AUTOSAR XML (schema 4-3-0)
package /ComponentTypes
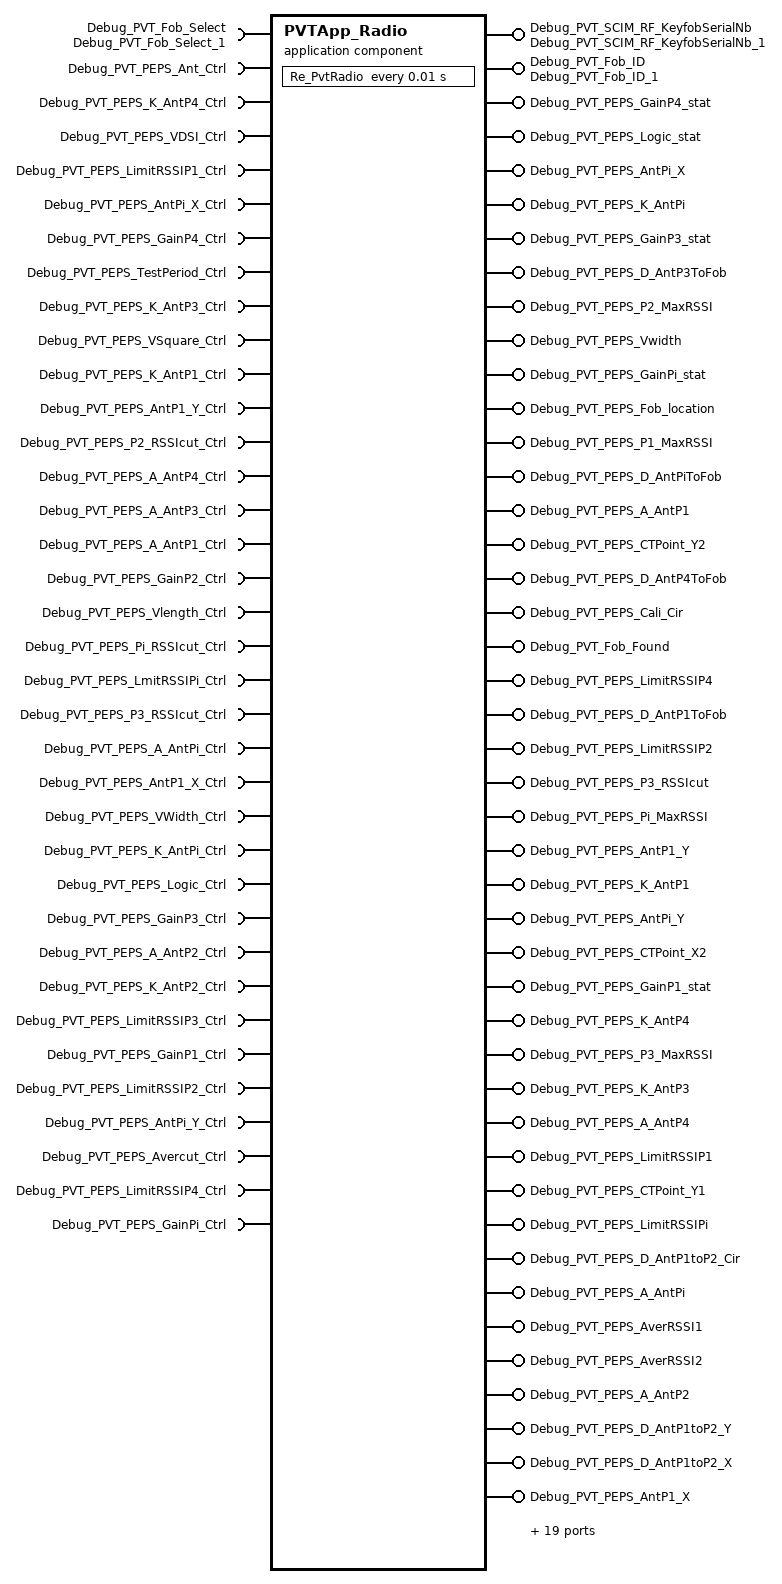
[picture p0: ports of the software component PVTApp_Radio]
  application sw component type PVTApp_Radio
    63 x provide port:
      Debug_PVT_SCIM_RF_KeyfobSerialNb: nonqueued-sender-com-spec{data-element=Debug_PVT_SCIM_RF_KeyfobSerialNb, init-value=0}, provided-interface=Debug_PVT_SCIM_RF_KeyfobSerialNb_1
      Debug_PVT_Fob_ID: nonqueued-sender-com-spec{data-element=Debug_PVT_Fob_ID, init-value=0}, provided-interface=Debug_PVT_Fob_ID_1
      Debug_PVT_PEPS_GainP4_stat: nonqueued-sender-com-spec{data-element=Debug_PVT_PEPS_GainP4_stat, init-value=0}, provided-interface=Debug_PVT_PEPS_GainP4_stat
      Debug_PVT_PEPS_Logic_stat: nonqueued-sender-com-spec{data-element=Debug_PVT_PEPS_Logic_stat, init-value=0}, provided-interface=Debug_PVT_PEPS_Logic_stat
      Debug_PVT_PEPS_AntPi_X: nonqueued-sender-com-spec{data-element=Debug_PVT_PEPS_AntPi_X, init-value=0}, provided-interface=Debug_PVT_PEPS_AntPi_X
      Debug_PVT_PEPS_K_AntPi: nonqueued-sender-com-spec{data-element=Debug_PVT_PEPS_K_AntPi, init-value=0}, provided-interface=Debug_PVT_PEPS_K_AntPi
      Debug_PVT_PEPS_GainP3_stat: nonqueued-sender-com-spec{data-element=Debug_PVT_PEPS_GainP3_stat, init-value=0}, provided-interface=Debug_PVT_PEPS_GainP3_stat
      Debug_PVT_PEPS_D_AntP3ToFob: nonqueued-sender-com-spec{data-element=Debug_PVT_PEPS_D_AntP3ToFob, init-value=0}, provided-interface=Debug_PVT_PEPS_D_AntP3ToFob
      Debug_PVT_PEPS_P2_MaxRSSI: nonqueued-sender-com-spec{data-element=Debug_PVT_PEPS_P2_MaxRSSI, init-value=0}, provided-interface=Debug_PVT_PEPS_P2_MaxRSSI
      Debug_PVT_PEPS_Vwidth: nonqueued-sender-com-spec{data-element=Debug_PVT_PEPS_Vwidth, init-value=0}, provided-interface=Debug_PVT_PEPS_Vwidth
      Debug_PVT_PEPS_GainPi_stat: nonqueued-sender-com-spec{data-element=Debug_PVT_PEPS_GainPi_stat, init-value=0}, provided-interface=Debug_PVT_PEPS_GainPi_stat
      Debug_PVT_PEPS_Fob_location: nonqueued-sender-com-spec{data-element=Debug_PVT_PEPS_Fob_location, init-value=0}, provided-interface=Debug_PVT_PEPS_Fob_location
      Debug_PVT_PEPS_P1_MaxRSSI: nonqueued-sender-com-spec{data-element=Debug_PVT_PEPS_P1_MaxRSSI, init-value=0}, provided-interface=Debug_PVT_PEPS_P1_MaxRSSI
      Debug_PVT_PEPS_D_AntPiToFob: nonqueued-sender-com-spec{data-element=Debug_PVT_PEPS_D_AntPiToFob, init-value=0}, provided-interface=Debug_PVT_PEPS_D_AntPiToFob
      Debug_PVT_PEPS_A_AntP1: nonqueued-sender-com-spec{data-element=Debug_PVT_PEPS_A_AntP1, init-value=0}, provided-interface=Debug_PVT_PEPS_A_AntP1
      Debug_PVT_PEPS_CTPoint_Y2: nonqueued-sender-com-spec{data-element=Debug_PVT_PEPS_CTPoint_Y2, init-value=0}, provided-interface=Debug_PVT_PEPS_CTPoint_Y2
      Debug_PVT_PEPS_D_AntP4ToFob: nonqueued-sender-com-spec{data-element=Debug_PVT_PEPS_D_AntP4ToFob, init-value=0}, provided-interface=Debug_PVT_PEPS_D_AntP4ToFob
      Debug_PVT_PEPS_Cali_Cir: nonqueued-sender-com-spec{data-element=Debug_PVT_PEPS_Cali_Cir, init-value=0}, provided-interface=Debug_PVT_PEPS_Cali_Cir
      Debug_PVT_Fob_Found: nonqueued-sender-com-spec{data-element=Debug_PVT_Fob_Found, init-value=0}, provided-interface=Debug_PVT_Fob_Found
      Debug_PVT_PEPS_LimitRSSIP4: nonqueued-sender-com-spec{data-element=Debug_PVT_PEPS_LimitRSSIP4, init-value=0}, provided-interface=Debug_PVT_PEPS_LimitRSSIP4
      Debug_PVT_PEPS_D_AntP1ToFob: nonqueued-sender-com-spec{data-element=Debug_PVT_PEPS_D_AntP1ToFob, init-value=0}, provided-interface=Debug_PVT_PEPS_D_AntP1ToFob
      Debug_PVT_PEPS_LimitRSSIP2: nonqueued-sender-com-spec{data-element=Debug_PVT_PEPS_LimitRSSIP2, init-value=0}, provided-interface=Debug_PVT_PEPS_LimitRSSIP2
      Debug_PVT_PEPS_P3_RSSIcut: nonqueued-sender-com-spec{data-element=Debug_PVT_PEPS_P3_RSSIcut, init-value=0}, provided-interface=Debug_PVT_PEPS_P3_RSSIcut
      Debug_PVT_PEPS_Pi_MaxRSSI: nonqueued-sender-com-spec{data-element=Debug_PVT_PEPS_Pi_MaxRSSI, init-value=0}, provided-interface=Debug_PVT_PEPS_Pi_MaxRSSI
      Debug_PVT_PEPS_AntP1_Y: nonqueued-sender-com-spec{data-element=Debug_PVT_PEPS_AntP1_Y, init-value=0}, provided-interface=Debug_PVT_PEPS_AntP1_Y
      Debug_PVT_PEPS_K_AntP1: nonqueued-sender-com-spec{data-element=Debug_PVT_PEPS_K_AntP1, init-value=0}, provided-interface=Debug_PVT_PEPS_K_AntP1
      Debug_PVT_PEPS_AntPi_Y: nonqueued-sender-com-spec{data-element=Debug_PVT_PEPS_AntPi_Y, init-value=0}, provided-interface=Debug_PVT_PEPS_AntPi_Y
      Debug_PVT_PEPS_CTPoint_X2: nonqueued-sender-com-spec{data-element=Debug_PVT_PEPS_CTPoint_X2, init-value=0}, provided-interface=Debug_PVT_PEPS_CTPoint_X2
      Debug_PVT_PEPS_GainP1_stat: nonqueued-sender-com-spec{data-element=Debug_PVT_PEPS_GainP1_stat, init-value=0}, provided-interface=Debug_PVT_PEPS_GainP1_stat
      Debug_PVT_PEPS_K_AntP4: nonqueued-sender-com-spec{data-element=Debug_PVT_PEPS_K_AntP4, init-value=0}, provided-interface=Debug_PVT_PEPS_K_AntP4
      Debug_PVT_PEPS_P3_MaxRSSI: nonqueued-sender-com-spec{data-element=Debug_PVT_PEPS_P3_MaxRSSI, init-value=0}, provided-interface=Debug_PVT_PEPS_P3_MaxRSSI
      Debug_PVT_PEPS_K_AntP3: nonqueued-sender-com-spec{data-element=Debug_PVT_PEPS_K_AntP3, init-value=0}, provided-interface=Debug_PVT_PEPS_K_AntP3
      Debug_PVT_PEPS_A_AntP4: nonqueued-sender-com-spec{data-element=Debug_PVT_PEPS_A_AntP4, init-value=0}, provided-interface=Debug_PVT_PEPS_A_AntP4
      Debug_PVT_PEPS_LimitRSSIP1: nonqueued-sender-com-spec{data-element=Debug_PVT_PEPS_LimitRSSIP1, init-value=0}, provided-interface=Debug_PVT_PEPS_LimitRSSIP1
      Debug_PVT_PEPS_CTPoint_Y1: nonqueued-sender-com-spec{data-element=Debug_PVT_PEPS_CTPoint_Y1, init-value=0}, provided-interface=Debug_PVT_PEPS_CTPoint_Y1
      Debug_PVT_PEPS_LimitRSSIPi: nonqueued-sender-com-spec{data-element=Debug_PVT_PEPS_LimitRSSIPi, init-value=0}, provided-interface=Debug_PVT_PEPS_LimitRSSIPi
      Debug_PVT_PEPS_D_AntP1toP2_Cir: nonqueued-sender-com-spec{data-element=Debug_PVT_PEPS_D_AntP1toP2_Cir, init-value=0}, provided-interface=Debug_PVT_PEPS_D_AntP1toP2_Cir
      Debug_PVT_PEPS_A_AntPi: nonqueued-sender-com-spec{data-element=Debug_PVT_PEPS_A_AntPi, init-value=0}, provided-interface=Debug_PVT_PEPS_A_AntPi
      Debug_PVT_PEPS_AverRSSI1: nonqueued-sender-com-spec{data-element=Debug_PVT_PEPS_AverRSSI1, init-value=0}, provided-interface=Debug_PVT_PEPS_AverRSSI1
      Debug_PVT_PEPS_AverRSSI2: nonqueued-sender-com-spec{data-element=Debug_PVT_PEPS_AverRSSI2, init-value=0}, provided-interface=Debug_PVT_PEPS_AverRSSI2
      Debug_PVT_PEPS_A_AntP2: nonqueued-sender-com-spec{data-element=Debug_PVT_PEPS_A_AntP2, init-value=0}, provided-interface=Debug_PVT_PEPS_A_AntP2
      Debug_PVT_PEPS_D_AntP1toP2_Y: nonqueued-sender-com-spec{data-element=Debug_PVT_PEPS_D_AntP1toP2_Y, init-value=0}, provided-interface=Debug_PVT_PEPS_D_AntP1toP2_Y
      Debug_PVT_PEPS_D_AntP1toP2_X: nonqueued-sender-com-spec{data-element=Debug_PVT_PEPS_D_AntP1toP2_X, init-value=0}, provided-interface=Debug_PVT_PEPS_D_AntP1toP2_X
      Debug_PVT_PEPS_AntP1_X: nonqueued-sender-com-spec{data-element=Debug_PVT_PEPS_AntP1_X, init-value=0}, provided-interface=Debug_PVT_PEPS_AntP1_X
      Debug_PVT_PEPS_Vlength: nonqueued-sender-com-spec{data-element=Debug_PVT_PEPS_Vlength, init-value=0}, provided-interface=Debug_PVT_PEPS_Vlength
      Debug_PVT_PEPS_AntCtrl_stat: nonqueued-sender-com-spec{data-element=Debug_PVT_PEPS_AntCtrl_stat, init-value=0}, provided-interface=Debug_PVT_PEPS_AntCtrl_stat
      Debug_PVT_PEPS_Vsquare: nonqueued-sender-com-spec{data-element=Debug_PVT_PEPS_Vsquare, init-value=0}, provided-interface=Debug_PVT_PEPS_Vsquare
      Debug_PVT_PEPS_D_AntP2ToFob: nonqueued-sender-com-spec{data-element=Debug_PVT_PEPS_D_AntP2ToFob, init-value=0}, provided-interface=Debug_PVT_PEPS_D_AntP2ToFob
      Debug_PVT_PEPS_K_AntP2: nonqueued-sender-com-spec{data-element=Debug_PVT_PEPS_K_AntP2, init-value=0}, provided-interface=Debug_PVT_PEPS_K_AntP2
      Debug_PVT_PEPS_P2_RSSIcut: nonqueued-sender-com-spec{data-element=Debug_PVT_PEPS_P2_RSSIcut, init-value=0}, provided-interface=Debug_PVT_PEPS_P2_RSSIcut
      Debug_PVT_PEPS_GainP2_stat: nonqueued-sender-com-spec{data-element=Debug_PVT_PEPS_GainP2_stat, init-value=0}, provided-interface=Debug_PVT_PEPS_GainP2_stat
      Debug_PVT_PEPS_A_AntP3: nonqueued-sender-com-spec{data-element=Debug_PVT_PEPS_A_AntP3, init-value=0}, provided-interface=Debug_PVT_PEPS_A_AntP3
      Debug_PVT_PEPS_LimitRSSIP3: nonqueued-sender-com-spec{data-element=Debug_PVT_PEPS_LimitRSSIP3, init-value=0}, provided-interface=Debug_PVT_PEPS_LimitRSSIP3
      Debug_PVT_PEPS_CTPoint_X1: nonqueued-sender-com-spec{data-element=Debug_PVT_PEPS_CTPoint_X1, init-value=0}, provided-interface=Debug_PVT_PEPS_CTPoint_X1
      Debug_PVT_PEPS_VDSI_stat: nonqueued-sender-com-spec{data-element=Debug_PVT_PEPS_VDSI_stat, init-value=0}, provided-interface=Debug_PVT_PEPS_VDSI_stat
      Debug_PVT_SCIM_RF_RollingCounter: nonqueued-sender-com-spec{data-element=Debug_PVT_SCIM_RF_RollingCounter, init-value=0}, provided-interface=Debug_PVT_SCIM_RF_RollingCounter_1
      Debug_PVT_PEPS_P4_MaxRSSI: nonqueued-sender-com-spec{data-element=Debug_PVT_PEPS_P4_MaxRSSI, init-value=0}, provided-interface=Debug_PVT_PEPS_P4_MaxRSSI
      Debug_PVT_PEPS_K_Cir: nonqueued-sender-com-spec{data-element=Debug_PVT_PEPS_K_Cir, init-value=0}, provided-interface=Debug_PVT_PEPS_K_Cir
      Debug_PVT_Fob_RF_RollingCounter: nonqueued-sender-com-spec{data-element=Debug_PVT_Fob_RF_RollingCounter, init-value=0}, provided-interface=Debug_PVT_Fob_RF_RollingCounter_1
      Debug_PVT_PEPS_DecRSSI: nonqueued-sender-com-spec{data-element=Debug_PVT_PEPS_DecRSSI, init-value=0}, provided-interface=Debug_PVT_PEPS_DecRSSI
      Debug_PVT_PEPS_Avercut: nonqueued-sender-com-spec{data-element=Debug_PVT_PEPS_Avercut, init-value=0}, provided-interface=Debug_PVT_PEPS_Avercut
      Debug_PVT_PEPS_TestPeriod_stat: nonqueued-sender-com-spec{data-element=Debug_PVT_PEPS_TestPeriod_stat, init-value=0}, provided-interface=Debug_PVT_PEPS_TestPeriod_stat
      Debug_PVT_PEPS_Pi_RSSIcut: nonqueued-sender-com-spec{data-element=Debug_PVT_PEPS_Pi_RSSIcut, init-value=0}, provided-interface=Debug_PVT_PEPS_Pi_RSSIcut
    36 x require port:
      Debug_PVT_Fob_Select: nonqueued-receiver-com-spec{data-element=Debug_PVT_Fob_Select, init-value=0}, required-interface=Debug_PVT_Fob_Select_1
      Debug_PVT_PEPS_Ant_Ctrl: nonqueued-receiver-com-spec{data-element=Debug_PVT_PEPS_Ant_Ctrl, init-value=0}, required-interface=Debug_PVT_PEPS_Ant_Ctrl
      Debug_PVT_PEPS_K_AntP4_Ctrl: nonqueued-receiver-com-spec{data-element=Debug_PVT_PEPS_K_AntP4_Ctrl, init-value=0}, required-interface=Debug_PVT_PEPS_K_AntP4_Ctrl
      Debug_PVT_PEPS_VDSI_Ctrl: nonqueued-receiver-com-spec{data-element=Debug_PVT_PEPS_VDSI_Ctrl, init-value=0}, required-interface=Debug_PVT_PEPS_VDSI_Ctrl
      Debug_PVT_PEPS_LimitRSSIP1_Ctrl: nonqueued-receiver-com-spec{data-element=Debug_PVT_PEPS_LimitRSSIP1_Ctrl, init-value=0}, required-interface=Debug_PVT_PEPS_LimitRSSIP1_Ctrl
      Debug_PVT_PEPS_AntPi_X_Ctrl: nonqueued-receiver-com-spec{data-element=Debug_PVT_PEPS_AntPi_X_Ctrl, init-value=0}, required-interface=Debug_PVT_PEPS_AntPi_X_Ctrl
      Debug_PVT_PEPS_GainP4_Ctrl: nonqueued-receiver-com-spec{data-element=Debug_PVT_PEPS_GainP4_Ctrl, init-value=0}, required-interface=Debug_PVT_PEPS_GainP4_Ctrl
      Debug_PVT_PEPS_TestPeriod_Ctrl: nonqueued-receiver-com-spec{data-element=Debug_PVT_PEPS_TestPeriod_Ctrl, init-value=0}, required-interface=Debug_PVT_PEPS_TestPeriod_Ctrl
      Debug_PVT_PEPS_K_AntP3_Ctrl: nonqueued-receiver-com-spec{data-element=Debug_PVT_PEPS_K_AntP3_Ctrl, init-value=0}, required-interface=Debug_PVT_PEPS_K_AntP3_Ctrl
      Debug_PVT_PEPS_VSquare_Ctrl: nonqueued-receiver-com-spec{data-element=Debug_PVT_PEPS_VSquare_Ctrl, init-value=0}, required-interface=Debug_PVT_PEPS_VSquare_Ctrl
      Debug_PVT_PEPS_K_AntP1_Ctrl: nonqueued-receiver-com-spec{data-element=Debug_PVT_PEPS_K_AntP1_Ctrl, init-value=0}, required-interface=Debug_PVT_PEPS_K_AntP1_Ctrl
      Debug_PVT_PEPS_AntP1_Y_Ctrl: nonqueued-receiver-com-spec{data-element=Debug_PVT_PEPS_AntP1_Y_Ctrl, init-value=0}, required-interface=Debug_PVT_PEPS_AntP1_Y_Ctrl
      Debug_PVT_PEPS_P2_RSSIcut_Ctrl: nonqueued-receiver-com-spec{data-element=Debug_PVT_PEPS_P2_RSSIcut_Ctrl, init-value=0}, required-interface=Debug_PVT_PEPS_P2_RSSIcut_Ctrl
      Debug_PVT_PEPS_A_AntP4_Ctrl: nonqueued-receiver-com-spec{data-element=Debug_PVT_PEPS_A_AntP4_Ctrl, init-value=0}, required-interface=Debug_PVT_PEPS_A_AntP4_Ctrl
      Debug_PVT_PEPS_A_AntP3_Ctrl: nonqueued-receiver-com-spec{data-element=Debug_PVT_PEPS_A_AntP3_Ctrl, init-value=0}, required-interface=Debug_PVT_PEPS_A_AntP3_Ctrl
      Debug_PVT_PEPS_A_AntP1_Ctrl: nonqueued-receiver-com-spec{data-element=Debug_PVT_PEPS_A_AntP1_Ctrl, init-value=0}, required-interface=Debug_PVT_PEPS_A_AntP1_Ctrl
      Debug_PVT_PEPS_GainP2_Ctrl: nonqueued-receiver-com-spec{data-element=Debug_PVT_PEPS_GainP2_Ctrl, init-value=0}, required-interface=Debug_PVT_PEPS_GainP2_Ctrl
      Debug_PVT_PEPS_Vlength_Ctrl: nonqueued-receiver-com-spec{data-element=Debug_PVT_PEPS_Vlength_Ctrl, init-value=0}, required-interface=Debug_PVT_PEPS_Vlength_Ctrl
      Debug_PVT_PEPS_Pi_RSSIcut_Ctrl: nonqueued-receiver-com-spec{data-element=Debug_PVT_PEPS_Pi_RSSIcut_Ctrl, init-value=0}, required-interface=Debug_PVT_PEPS_Pi_RSSIcut_Ctrl
      Debug_PVT_PEPS_LmitRSSIPi_Ctrl: nonqueued-receiver-com-spec{data-element=Debug_PVT_PEPS_LmitRSSIPi_Ctrl, init-value=0}, required-interface=Debug_PVT_PEPS_LmitRSSIPi_Ctrl
      Debug_PVT_PEPS_P3_RSSIcut_Ctrl: nonqueued-receiver-com-spec{data-element=Debug_PVT_PEPS_P3_RSSIcut_Ctrl, init-value=0}, required-interface=Debug_PVT_PEPS_P3_RSSIcut_Ctrl
      Debug_PVT_PEPS_A_AntPi_Ctrl: nonqueued-receiver-com-spec{data-element=Debug_PVT_PEPS_A_AntPi_Ctrl, init-value=0}, required-interface=Debug_PVT_PEPS_A_AntPi_Ctrl
      Debug_PVT_PEPS_AntP1_X_Ctrl: nonqueued-receiver-com-spec{data-element=Debug_PVT_PEPS_AntP1_X_Ctrl, init-value=0}, required-interface=Debug_PVT_PEPS_AntP1_X_Ctrl
      Debug_PVT_PEPS_VWidth_Ctrl: nonqueued-receiver-com-spec{data-element=Debug_PVT_PEPS_VWidth_Ctrl, init-value=0}, required-interface=Debug_PVT_PEPS_VWidth_Ctrl
      Debug_PVT_PEPS_K_AntPi_Ctrl: nonqueued-receiver-com-spec{data-element=Debug_PVT_PEPS_K_AntPi_Ctrl, init-value=0}, required-interface=Debug_PVT_PEPS_K_AntPi_Ctrl
      Debug_PVT_PEPS_Logic_Ctrl: nonqueued-receiver-com-spec{data-element=Debug_PVT_PEPS_Logic_Ctrl, init-value=0}, required-interface=Debug_PVT_PEPS_Logic_Ctrl
      Debug_PVT_PEPS_GainP3_Ctrl: nonqueued-receiver-com-spec{data-element=Debug_PVT_PEPS_GainP3_Ctrl, init-value=0}, required-interface=Debug_PVT_PEPS_GainP3_Ctrl
      Debug_PVT_PEPS_A_AntP2_Ctrl: nonqueued-receiver-com-spec{data-element=Debug_PVT_PEPS_A_AntP2_Ctrl, init-value=0}, required-interface=Debug_PVT_PEPS_A_AntP2_Ctrl
      Debug_PVT_PEPS_K_AntP2_Ctrl: nonqueued-receiver-com-spec{data-element=Debug_PVT_PEPS_K_AntP2_Ctrl, init-value=0}, required-interface=Debug_PVT_PEPS_K_AntP2_Ctrl
      Debug_PVT_PEPS_LimitRSSIP3_Ctrl: nonqueued-receiver-com-spec{data-element=Debug_PVT_PEPS_LimitRSSIP3_Ctrl, init-value=0}, required-interface=Debug_PVT_PEPS_LimitRSSIP3_Ctrl
      Debug_PVT_PEPS_GainP1_Ctrl: nonqueued-receiver-com-spec{data-element=Debug_PVT_PEPS_GainP1_Ctrl, init-value=0}, required-interface=Debug_PVT_PEPS_GainP1_Ctrl
      Debug_PVT_PEPS_LimitRSSIP2_Ctrl: nonqueued-receiver-com-spec{data-element=Debug_PVT_PEPS_LimitRSSIP2_Ctrl, init-value=0}, required-interface=Debug_PVT_PEPS_LimitRSSIP2_Ctrl
      Debug_PVT_PEPS_AntPi_Y_Ctrl: nonqueued-receiver-com-spec{data-element=Debug_PVT_PEPS_AntPi_Y_Ctrl, init-value=0}, required-interface=Debug_PVT_PEPS_AntPi_Y_Ctrl
      Debug_PVT_PEPS_Avercut_Ctrl: nonqueued-receiver-com-spec{data-element=Debug_PVT_PEPS_Avercut_Ctrl, init-value=0}, required-interface=Debug_PVT_PEPS_Avercut_Ctrl
      Debug_PVT_PEPS_LimitRSSIP4_Ctrl: nonqueued-receiver-com-spec{data-element=Debug_PVT_PEPS_LimitRSSIP4_Ctrl, init-value=0}, required-interface=Debug_PVT_PEPS_LimitRSSIP4_Ctrl
      Debug_PVT_PEPS_GainPi_Ctrl: nonqueued-receiver-com-spec{data-element=Debug_PVT_PEPS_GainPi_Ctrl, init-value=0}, required-interface=Debug_PVT_PEPS_GainPi_Ctrl
    behavior PVTApp_Radio_InternalBehavior
      timing event TMT_Re_PvtRadio: start-on-event=Re_PvtRadio, period=0.01
      runnable Re_PvtRadio
        data-receive-point-by-arguments:
          36 x access:
            REC_Debug_PVT_Fob_Select_Debug_PVT_Fob_Select: accessed-variable=Debug_PVT_Fob_Select.Debug_PVT_Fob_Select
            REC_Debug_PVT_PEPS_A_AntP{1..4}_Ctrl_Debug_PVT_PEPS_A_AntP{1..4}_Ctrl: accessed-variable=Debug_PVT_PEPS_A_AntP{1..4}_Ctrl.Debug_PVT_PEPS_A_AntP{1..4}_Ctrl
            REC_Debug_PVT_PEPS_A_AntPi_Ctrl_Debug_PVT_PEPS_A_AntPi_Ctrl: accessed-variable=Debug_PVT_PEPS_A_AntPi_Ctrl.Debug_PVT_PEPS_A_AntPi_Ctrl
            REC_Debug_PVT_PEPS_AntP1_X_Ctrl_Debug_PVT_PEPS_AntP1_X_Ctrl: accessed-variable=Debug_PVT_PEPS_AntP1_X_Ctrl.Debug_PVT_PEPS_AntP1_X_Ctrl
            REC_Debug_PVT_PEPS_AntP1_Y_Ctrl_Debug_PVT_PEPS_AntP1_Y_Ctrl: accessed-variable=Debug_PVT_PEPS_AntP1_Y_Ctrl.Debug_PVT_PEPS_AntP1_Y_Ctrl
            REC_Debug_PVT_PEPS_AntPi_X_Ctrl_Debug_PVT_PEPS_AntPi_X_Ctrl: accessed-variable=Debug_PVT_PEPS_AntPi_X_Ctrl.Debug_PVT_PEPS_AntPi_X_Ctrl
            REC_Debug_PVT_PEPS_AntPi_Y_Ctrl_Debug_PVT_PEPS_AntPi_Y_Ctrl: accessed-variable=Debug_PVT_PEPS_AntPi_Y_Ctrl.Debug_PVT_PEPS_AntPi_Y_Ctrl
            REC_Debug_PVT_PEPS_Ant_Ctrl_Debug_PVT_PEPS_Ant_Ctrl: accessed-variable=Debug_PVT_PEPS_Ant_Ctrl.Debug_PVT_PEPS_Ant_Ctrl
            REC_Debug_PVT_PEPS_Avercut_Ctrl_Debug_PVT_PEPS_Avercut_Ctrl: accessed-variable=Debug_PVT_PEPS_Avercut_Ctrl.Debug_PVT_PEPS_Avercut_Ctrl
            REC_Debug_PVT_PEPS_GainP{1..4}_Ctrl_Debug_PVT_PEPS_GainP{1..4}_Ctrl: accessed-variable=Debug_PVT_PEPS_GainP{1..4}_Ctrl.Debug_PVT_PEPS_GainP{1..4}_Ctrl
            REC_Debug_PVT_PEPS_GainPi_Ctrl_Debug_PVT_PEPS_GainPi_Ctrl: accessed-variable=Debug_PVT_PEPS_GainPi_Ctrl.Debug_PVT_PEPS_GainPi_Ctrl
            REC_Debug_PVT_PEPS_K_AntP{1..4}_Ctrl_Debug_PVT_PEPS_K_AntP{1..4}_Ctrl: accessed-variable=Debug_PVT_PEPS_K_AntP{1..4}_Ctrl.Debug_PVT_PEPS_K_AntP{1..4}_Ctrl
            REC_Debug_PVT_PEPS_K_AntPi_Ctrl_Debug_PVT_PEPS_K_AntPi_Ctrl: accessed-variable=Debug_PVT_PEPS_K_AntPi_Ctrl.Debug_PVT_PEPS_K_AntPi_Ctrl
            REC_Debug_PVT_PEPS_LimitRSSIP{1..4}_Ctrl_Debug_PVT_PEPS_LimitRSSIP{1..4}_Ctrl: accessed-variable=Debug_PVT_PEPS_LimitRSSIP{1..4}_Ctrl.Debug_PVT_PEPS_LimitRSSIP{1..4}_Ctrl
            REC_Debug_PVT_PEPS_LmitRSSIPi_Ctrl_Debug_PVT_PEPS_LmitRSSIPi_Ctrl: accessed-variable=Debug_PVT_PEPS_LmitRSSIPi_Ctrl.Debug_PVT_PEPS_LmitRSSIPi_Ctrl
            REC_Debug_PVT_PEPS_Logic_Ctrl_Debug_PVT_PEPS_Logic_Ctrl: accessed-variable=Debug_PVT_PEPS_Logic_Ctrl.Debug_PVT_PEPS_Logic_Ctrl
            REC_Debug_PVT_PEPS_P2_RSSIcut_Ctrl_Debug_PVT_PEPS_P2_RSSIcut_Ctrl: accessed-variable=Debug_PVT_PEPS_P2_RSSIcut_Ctrl.Debug_PVT_PEPS_P2_RSSIcut_Ctrl
            REC_Debug_PVT_PEPS_P3_RSSIcut_Ctrl_Debug_PVT_PEPS_P3_RSSIcut_Ctrl: accessed-variable=Debug_PVT_PEPS_P3_RSSIcut_Ctrl.Debug_PVT_PEPS_P3_RSSIcut_Ctrl
            REC_Debug_PVT_PEPS_Pi_RSSIcut_Ctrl_Debug_PVT_PEPS_Pi_RSSIcut_Ctrl: accessed-variable=Debug_PVT_PEPS_Pi_RSSIcut_Ctrl.Debug_PVT_PEPS_Pi_RSSIcut_Ctrl
            REC_Debug_PVT_PEPS_TestPeriod_Ctrl_Debug_PVT_PEPS_TestPeriod_Ctrl: accessed-variable=Debug_PVT_PEPS_TestPeriod_Ctrl.Debug_PVT_PEPS_TestPeriod_Ctrl
            REC_Debug_PVT_PEPS_VDSI_Ctrl_Debug_PVT_PEPS_VDSI_Ctrl: accessed-variable=Debug_PVT_PEPS_VDSI_Ctrl.Debug_PVT_PEPS_VDSI_Ctrl
            REC_Debug_PVT_PEPS_VSquare_Ctrl_Debug_PVT_PEPS_VSquare_Ctrl: accessed-variable=Debug_PVT_PEPS_VSquare_Ctrl.Debug_PVT_PEPS_VSquare_Ctrl
            REC_Debug_PVT_PEPS_VWidth_Ctrl_Debug_PVT_PEPS_VWidth_Ctrl: accessed-variable=Debug_PVT_PEPS_VWidth_Ctrl.Debug_PVT_PEPS_VWidth_Ctrl
            REC_Debug_PVT_PEPS_Vlength_Ctrl_Debug_PVT_PEPS_Vlength_Ctrl: accessed-variable=Debug_PVT_PEPS_Vlength_Ctrl.Debug_PVT_PEPS_Vlength_Ctrl
        data-send-points:
          63 x access:
            SEND_Debug_PVT_Fob_Found_Debug_PVT_Fob_Found: accessed-variable=Debug_PVT_Fob_Found.Debug_PVT_Fob_Found
            SEND_Debug_PVT_Fob_ID_Debug_PVT_Fob_ID: accessed-variable=Debug_PVT_Fob_ID.Debug_PVT_Fob_ID
            SEND_Debug_PVT_Fob_RF_RollingCounter_Debug_PVT_Fob_RF_RollingCounter: accessed-variable=Debug_PVT_Fob_RF_RollingCounter.Debug_PVT_Fob_RF_RollingCounter
            SEND_Debug_PVT_PEPS_A_AntP{1..4}_Debug_PVT_PEPS_A_AntP{1..4}: accessed-variable=Debug_PVT_PEPS_A_AntP{1..4}.Debug_PVT_PEPS_A_AntP{1..4}
            SEND_Debug_PVT_PEPS_A_AntPi_Debug_PVT_PEPS_A_AntPi: accessed-variable=Debug_PVT_PEPS_A_AntPi.Debug_PVT_PEPS_A_AntPi
            SEND_Debug_PVT_PEPS_AntCtrl_stat_Debug_PVT_PEPS_AntCtrl_stat: accessed-variable=Debug_PVT_PEPS_AntCtrl_stat.Debug_PVT_PEPS_AntCtrl_stat
            SEND_Debug_PVT_PEPS_AntP1_X_Debug_PVT_PEPS_AntP1_X: accessed-variable=Debug_PVT_PEPS_AntP1_X.Debug_PVT_PEPS_AntP1_X
            SEND_Debug_PVT_PEPS_AntP1_Y_Debug_PVT_PEPS_AntP1_Y: accessed-variable=Debug_PVT_PEPS_AntP1_Y.Debug_PVT_PEPS_AntP1_Y
            SEND_Debug_PVT_PEPS_AntPi_X_Debug_PVT_PEPS_AntPi_X: accessed-variable=Debug_PVT_PEPS_AntPi_X.Debug_PVT_PEPS_AntPi_X
            SEND_Debug_PVT_PEPS_AntPi_Y_Debug_PVT_PEPS_AntPi_Y: accessed-variable=Debug_PVT_PEPS_AntPi_Y.Debug_PVT_PEPS_AntPi_Y
            SEND_Debug_PVT_PEPS_Avercut_Debug_PVT_PEPS_Avercut: accessed-variable=Debug_PVT_PEPS_Avercut.Debug_PVT_PEPS_Avercut
            SEND_Debug_PVT_PEPS_AverRSSI1_Debug_PVT_PEPS_AverRSSI1: accessed-variable=Debug_PVT_PEPS_AverRSSI1.Debug_PVT_PEPS_AverRSSI1
            SEND_Debug_PVT_PEPS_AverRSSI2_Debug_PVT_PEPS_AverRSSI2: accessed-variable=Debug_PVT_PEPS_AverRSSI2.Debug_PVT_PEPS_AverRSSI2
            SEND_Debug_PVT_PEPS_Cali_Cir_Debug_PVT_PEPS_Cali_Cir: accessed-variable=Debug_PVT_PEPS_Cali_Cir.Debug_PVT_PEPS_Cali_Cir
            SEND_Debug_PVT_PEPS_CTPoint_X1_Debug_PVT_PEPS_CTPoint_X1: accessed-variable=Debug_PVT_PEPS_CTPoint_X1.Debug_PVT_PEPS_CTPoint_X1
            SEND_Debug_PVT_PEPS_CTPoint_X2_Debug_PVT_PEPS_CTPoint_X2: accessed-variable=Debug_PVT_PEPS_CTPoint_X2.Debug_PVT_PEPS_CTPoint_X2
            SEND_Debug_PVT_PEPS_CTPoint_Y1_Debug_PVT_PEPS_CTPoint_Y1: accessed-variable=Debug_PVT_PEPS_CTPoint_Y1.Debug_PVT_PEPS_CTPoint_Y1
            SEND_Debug_PVT_PEPS_CTPoint_Y2_Debug_PVT_PEPS_CTPoint_Y2: accessed-variable=Debug_PVT_PEPS_CTPoint_Y2.Debug_PVT_PEPS_CTPoint_Y2
            SEND_Debug_PVT_PEPS_D_AntP1ToFob_Debug_PVT_PEPS_D_AntP1ToFob: accessed-variable=Debug_PVT_PEPS_D_AntP1ToFob.Debug_PVT_PEPS_D_AntP1ToFob
            SEND_Debug_PVT_PEPS_D_AntP1toP2_Cir_Debug_PVT_PEPS_D_AntP1toP2_Cir: accessed-variable=Debug_PVT_PEPS_D_AntP1toP2_Cir.Debug_PVT_PEPS_D_AntP1toP2_Cir
            SEND_Debug_PVT_PEPS_D_AntP1toP2_X_Debug_PVT_PEPS_D_AntP1toP2_X: accessed-variable=Debug_PVT_PEPS_D_AntP1toP2_X.Debug_PVT_PEPS_D_AntP1toP2_X
            SEND_Debug_PVT_PEPS_D_AntP1toP2_Y_Debug_PVT_PEPS_D_AntP1toP2_Y: accessed-variable=Debug_PVT_PEPS_D_AntP1toP2_Y.Debug_PVT_PEPS_D_AntP1toP2_Y
            SEND_Debug_PVT_PEPS_D_AntP{2..4}ToFob_Debug_PVT_PEPS_D_AntP{2..4}ToFob: accessed-variable=Debug_PVT_PEPS_D_AntP{2..4}ToFob.Debug_PVT_PEPS_D_AntP{2..4}ToFob
            SEND_Debug_PVT_PEPS_D_AntPiToFob_Debug_PVT_PEPS_D_AntPiToFob: accessed-variable=Debug_PVT_PEPS_D_AntPiToFob.Debug_PVT_PEPS_D_AntPiToFob
            SEND_Debug_PVT_PEPS_DecRSSI_Debug_PVT_PEPS_DecRSSI: accessed-variable=Debug_PVT_PEPS_DecRSSI.Debug_PVT_PEPS_DecRSSI
            SEND_Debug_PVT_PEPS_Fob_location_Debug_PVT_PEPS_Fob_location: accessed-variable=Debug_PVT_PEPS_Fob_location.Debug_PVT_PEPS_Fob_location
            SEND_Debug_PVT_PEPS_GainP{1..4}_stat_Debug_PVT_PEPS_GainP{1..4}_stat: accessed-variable=Debug_PVT_PEPS_GainP{1..4}_stat.Debug_PVT_PEPS_GainP{1..4}_stat
            SEND_Debug_PVT_PEPS_GainPi_stat_Debug_PVT_PEPS_GainPi_stat: accessed-variable=Debug_PVT_PEPS_GainPi_stat.Debug_PVT_PEPS_GainPi_stat
            SEND_Debug_PVT_PEPS_K_AntP{1..4}_Debug_PVT_PEPS_K_AntP{1..4}: accessed-variable=Debug_PVT_PEPS_K_AntP{1..4}.Debug_PVT_PEPS_K_AntP{1..4}
            SEND_Debug_PVT_PEPS_K_AntPi_Debug_PVT_PEPS_K_AntPi: accessed-variable=Debug_PVT_PEPS_K_AntPi.Debug_PVT_PEPS_K_AntPi
            SEND_Debug_PVT_PEPS_K_Cir_Debug_PVT_PEPS_K_Cir: accessed-variable=Debug_PVT_PEPS_K_Cir.Debug_PVT_PEPS_K_Cir
            SEND_Debug_PVT_PEPS_LimitRSSIP{1..4}_Debug_PVT_PEPS_LimitRSSIP{1..4}: accessed-variable=Debug_PVT_PEPS_LimitRSSIP{1..4}.Debug_PVT_PEPS_LimitRSSIP{1..4}
            SEND_Debug_PVT_PEPS_LimitRSSIPi_Debug_PVT_PEPS_LimitRSSIPi: accessed-variable=Debug_PVT_PEPS_LimitRSSIPi.Debug_PVT_PEPS_LimitRSSIPi
            SEND_Debug_PVT_PEPS_Logic_stat_Debug_PVT_PEPS_Logic_stat: accessed-variable=Debug_PVT_PEPS_Logic_stat.Debug_PVT_PEPS_Logic_stat
            SEND_Debug_PVT_PEPS_P1_MaxRSSI_Debug_PVT_PEPS_P1_MaxRSSI: accessed-variable=Debug_PVT_PEPS_P1_MaxRSSI.Debug_PVT_PEPS_P1_MaxRSSI
            SEND_Debug_PVT_PEPS_P2_MaxRSSI_Debug_PVT_PEPS_P2_MaxRSSI: accessed-variable=Debug_PVT_PEPS_P2_MaxRSSI.Debug_PVT_PEPS_P2_MaxRSSI
            SEND_Debug_PVT_PEPS_P2_RSSIcut_Debug_PVT_PEPS_P2_RSSIcut: accessed-variable=Debug_PVT_PEPS_P2_RSSIcut.Debug_PVT_PEPS_P2_RSSIcut
            SEND_Debug_PVT_PEPS_P3_MaxRSSI_Debug_PVT_PEPS_P3_MaxRSSI: accessed-variable=Debug_PVT_PEPS_P3_MaxRSSI.Debug_PVT_PEPS_P3_MaxRSSI
            SEND_Debug_PVT_PEPS_P3_RSSIcut_Debug_PVT_PEPS_P3_RSSIcut: accessed-variable=Debug_PVT_PEPS_P3_RSSIcut.Debug_PVT_PEPS_P3_RSSIcut
            SEND_Debug_PVT_PEPS_P4_MaxRSSI_Debug_PVT_PEPS_P4_MaxRSSI: accessed-variable=Debug_PVT_PEPS_P4_MaxRSSI.Debug_PVT_PEPS_P4_MaxRSSI
            SEND_Debug_PVT_PEPS_Pi_MaxRSSI_Debug_PVT_PEPS_Pi_MaxRSSI: accessed-variable=Debug_PVT_PEPS_Pi_MaxRSSI.Debug_PVT_PEPS_Pi_MaxRSSI
            SEND_Debug_PVT_PEPS_Pi_RSSIcut_Debug_PVT_PEPS_Pi_RSSIcut: accessed-variable=Debug_PVT_PEPS_Pi_RSSIcut.Debug_PVT_PEPS_Pi_RSSIcut
            SEND_Debug_PVT_PEPS_TestPeriod_stat_Debug_PVT_PEPS_TestPeriod_stat: accessed-variable=Debug_PVT_PEPS_TestPeriod_stat.Debug_PVT_PEPS_TestPeriod_stat
            SEND_Debug_PVT_PEPS_VDSI_stat_Debug_PVT_PEPS_VDSI_stat: accessed-variable=Debug_PVT_PEPS_VDSI_stat.Debug_PVT_PEPS_VDSI_stat
            SEND_Debug_PVT_PEPS_Vlength_Debug_PVT_PEPS_Vlength: accessed-variable=Debug_PVT_PEPS_Vlength.Debug_PVT_PEPS_Vlength
            SEND_Debug_PVT_PEPS_Vsquare_Debug_PVT_PEPS_Vsquare: accessed-variable=Debug_PVT_PEPS_Vsquare.Debug_PVT_PEPS_Vsquare
            SEND_Debug_PVT_PEPS_Vwidth_Debug_PVT_PEPS_Vwidth: accessed-variable=Debug_PVT_PEPS_Vwidth.Debug_PVT_PEPS_Vwidth
            SEND_Debug_PVT_SCIM_RF_KeyfobSerialNb_Debug_PVT_SCIM_RF_KeyfobSerialNb: accessed-variable=Debug_PVT_SCIM_RF_KeyfobSerialNb.Debug_PVT_SCIM_RF_KeyfobSerialNb
            SEND_Debug_PVT_SCIM_RF_RollingCounter_Debug_PVT_SCIM_RF_RollingCounter: accessed-variable=Debug_PVT_SCIM_RF_RollingCounter.Debug_PVT_SCIM_RF_RollingCounter
  swc implementation PVTApp_Radio_Implementation: behavior=PVTApp_Radio_InternalBehavior
